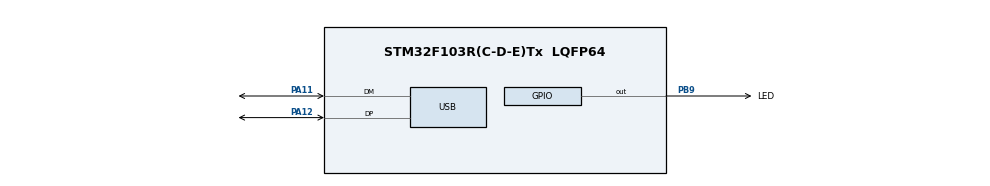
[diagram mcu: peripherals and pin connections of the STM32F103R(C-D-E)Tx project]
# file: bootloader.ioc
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Mcu.Family=STM32F1
Mcu.Name=STM32F103R(C-D-E)Tx
Mcu.Package=LQFP64
NVIC.PriorityGroup=NVIC_PRIORITYGROUP_4
NVIC.USB_LP_CAN1_RX0_IRQn=true\:2\:0\:true\:false\:true\:false\:true\:true
PA11.Mode=Device
PA11.Signal=USB_DM
PA12.Mode=Device
PA12.Signal=USB_DP
PA13.Mode=Serial_Wire
PA13.Signal=SYS_JTMS-SWDIO
PA14.Mode=Serial_Wire
PA14.Signal=SYS_JTCK-SWCLK
PB9.GPIO_Label=LED
PB9.Signal=GPIO_Output
PD0-OSC_IN.Mode=HSE-External-Oscillator
PD0-OSC_IN.Signal=RCC_OSC_IN
PD1-OSC_OUT.Mode=HSE-External-Oscillator
PD1-OSC_OUT.Signal=RCC_OSC_OUT
ProjectManager.HeapSize=0x200
ProjectManager.StackSize=0x400
ProjectManager.TargetToolchain=STM32CubeIDE
RCC.AHBFreq_Value=72000000
RCC.APB1CLKDivider=RCC_HCLK_DIV2
RCC.APB1Freq_Value=36000000
RCC.APB1TimFreq_Value=72000000
RCC.APB2Freq_Value=72000000
RCC.APB2TimFreq_Value=72000000
RCC.HCLKFreq_Value=72000000
RCC.PLLMUL=RCC_PLL_MUL9
RCC.PLLSourceVirtual=RCC_PLLSOURCE_HSE
RCC.SYSCLKFreq_VALUE=72000000
RCC.SYSCLKSource=RCC_SYSCLKSOURCE_PLLCLK
RCC.USBFreq_Value=48000000
RCC.USBPrescaler=RCC_USBCLKSOURCE_PLL_DIV1_5
USB_DEVICE.CLASS_NAME_FS=DFU
USB_DEVICE.USBD_DFU_MEDIA=@Internal Flash   /0x08000000/03*016Ka,6*32Kg
USB_DEVICE.VirtualMode=Dfu
USB_DEVICE.VirtualModeFS=Dfu_FS
VP_USB_DEVICE_VS_USB_DEVICE_DFU_FS.Mode=DFU_FS
board=custom

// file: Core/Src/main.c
/* USER CODE BEGIN Header */
/**
  ******************************************************************************
  * @file           : main.c
  * @brief          : Main program body
  ******************************************************************************
  * @attention
  *
  * Copyright (c) 2023 STMicroelectronics.
  * All rights reserved.
  *
  * This software is licensed under terms that can be found in the LICENSE file
  * in the root directory of this software component.
  * If no LICENSE file comes with this software, it is provided AS-IS.
  *
  ******************************************************************************
  */
/* USER CODE END Header */
#include "main.h"
#include "usb_device.h"

/* USER CODE BEGIN PD */
#define FLASH_APP_ADDR 0x800C000
/* USER CODE END PD */

/* USER CODE BEGIN PM */
//typedef void (*pFunction)(void);
/* USER CODE END PM */

void SystemClock_Config(void);
static void MX_GPIO_Init(void);

/* USER CODE BEGIN 0 */

/*
void Go2APP(void){
	uint32_t jumpaddress;
	pFunction jump_to_application;

	jumpaddress = *(uint32_t *) (FLASH_APP_ADDR + 4);

	jump_to_application = (pFunction) jumpaddress;
	//HAL_DeInit();
	__set_MSP(*(uint32_t *)FLASH_APP_ADDR);
	jump_to_application();

};
*/
/* USER CODE END 0 */

int main(void)
{

  /* MCU Configuration--------------------------------------------------------*/

  /* Reset of all peripherals, Initializes the Flash interface and the Systick. */
  HAL_Init();

  /* Configure the system clock */
  SystemClock_Config();

  /* USER CODE BEGIN SysInit */
  LL_APB2_GRP1_EnableClock(LL_APB2_GRP1_PERIPH_GPIOA);
  /* Pull USB D+ PIN to GND so USB Host detects device disconnect */
  LL_GPIO_SetPinMode(GPIOA,LL_GPIO_PIN_12, LL_GPIO_MODE_OUTPUT);
  LL_GPIO_SetPinSpeed(GPIOA, LL_GPIO_PIN_12, LL_GPIO_SPEED_FREQ_LOW);
  LL_GPIO_SetPinOutputType(GPIOA,LL_GPIO_PIN_12, LL_GPIO_OUTPUT_PUSHPULL);
  LL_GPIO_ResetOutputPin(GPIOA, LL_GPIO_PIN_12);

  LL_mDelay(100);
  /* USER CODE END SysInit */

  /* Initialize all configured peripherals */
  MX_GPIO_Init();
  MX_USB_DEVICE_Init();
  /* USER CODE BEGIN 2 */
  LL_GPIO_TogglePin(LED_GPIO_Port, LED_Pin);
  LL_GPIO_TogglePin(LED_GPIO_Port, LED_Pin);

  if (0){
  	  // bootloader section

    }
    else
    {

    //Go2APP();

  	//static uint32_t APP_ADDR = 0x800C0000; must be defined globally
      // Jump to the app code
    HAL_DeInit();
  	uint32_t jump_addr = *((__IO uint32_t*)(FLASH_APP_ADDR+4u));
  	//HAL_DeInit();

  	// Disable all interrupts
  	NVIC->ICER[0] = 0xFFFFFFFF;
  	NVIC->ICER[1] = 0xFFFFFFFF;
  	NVIC->ICER[2] = 0xFFFFFFFF;

  	NVIC->ICPR[0] = 0xFFFFFFFF;
  	NVIC->ICPR[1] = 0xFFFFFFFF;
  	NVIC->ICPR[2] = 0xFFFFFFFF;

  	/* deactivate SysTick */
  	SysTick->CTRL = 0;

  	/* Change the main stack pointer. */
  	SCB->VTOR = FLASH_APP_ADDR;
  	__set_MSP((*(__IO uint32_t*)FLASH_APP_ADDR));

  	((void (*) (void)) (jump_addr)) ();
    };
  /* USER CODE END 2 */

  /* Infinite loop */
  while (1)
  {

  }
}

void SystemClock_Config(void)
{
  LL_FLASH_SetLatency(LL_FLASH_LATENCY_2);
  while(LL_FLASH_GetLatency()!= LL_FLASH_LATENCY_2)
  {
  }
  LL_RCC_HSE_Enable();

   /* Wait till HSE is ready */
  while(LL_RCC_HSE_IsReady() != 1)
  {

  }
  LL_RCC_PLL_ConfigDomain_SYS(LL_RCC_PLLSOURCE_HSE_DIV_1, LL_RCC_PLL_MUL_9);
  LL_RCC_PLL_Enable();

   /* Wait till PLL is ready */
  while(LL_RCC_PLL_IsReady() != 1)
  {

  }
  LL_RCC_SetAHBPrescaler(LL_RCC_SYSCLK_DIV_1);
  LL_RCC_SetAPB1Prescaler(LL_RCC_APB1_DIV_2);
  LL_RCC_SetAPB2Prescaler(LL_RCC_APB2_DIV_1);
  LL_RCC_SetSysClkSource(LL_RCC_SYS_CLKSOURCE_PLL);

   /* Wait till System clock is ready */
  while(LL_RCC_GetSysClkSource() != LL_RCC_SYS_CLKSOURCE_STATUS_PLL)
  {

  }
  LL_SetSystemCoreClock(72000000);

   /* Update the time base */
  if (HAL_InitTick (TICK_INT_PRIORITY) != HAL_OK)
  {
    Error_Handler();
  }
  LL_RCC_SetUSBClockSource(LL_RCC_USB_CLKSOURCE_PLL_DIV_1_5);
}

static void MX_GPIO_Init(void)
{
  LL_GPIO_InitTypeDef GPIO_InitStruct = {0};

  /* GPIO Ports Clock Enable */
  LL_APB2_GRP1_EnableClock(LL_APB2_GRP1_PERIPH_GPIOD);
  LL_APB2_GRP1_EnableClock(LL_APB2_GRP1_PERIPH_GPIOA);
  LL_APB2_GRP1_EnableClock(LL_APB2_GRP1_PERIPH_GPIOB);

  /**/
  LL_GPIO_ResetOutputPin(LED_GPIO_Port, LED_Pin);

  /**/
  GPIO_InitStruct.Pin = LED_Pin;
  GPIO_InitStruct.Mode = LL_GPIO_MODE_OUTPUT;
  GPIO_InitStruct.Speed = LL_GPIO_SPEED_FREQ_LOW;
  GPIO_InitStruct.OutputType = LL_GPIO_OUTPUT_PUSHPULL;
  LL_GPIO_Init(LED_GPIO_Port, &GPIO_InitStruct);

}

void Error_Handler(void)
{
  __disable_irq();
  while (1)
  {
  }
}
